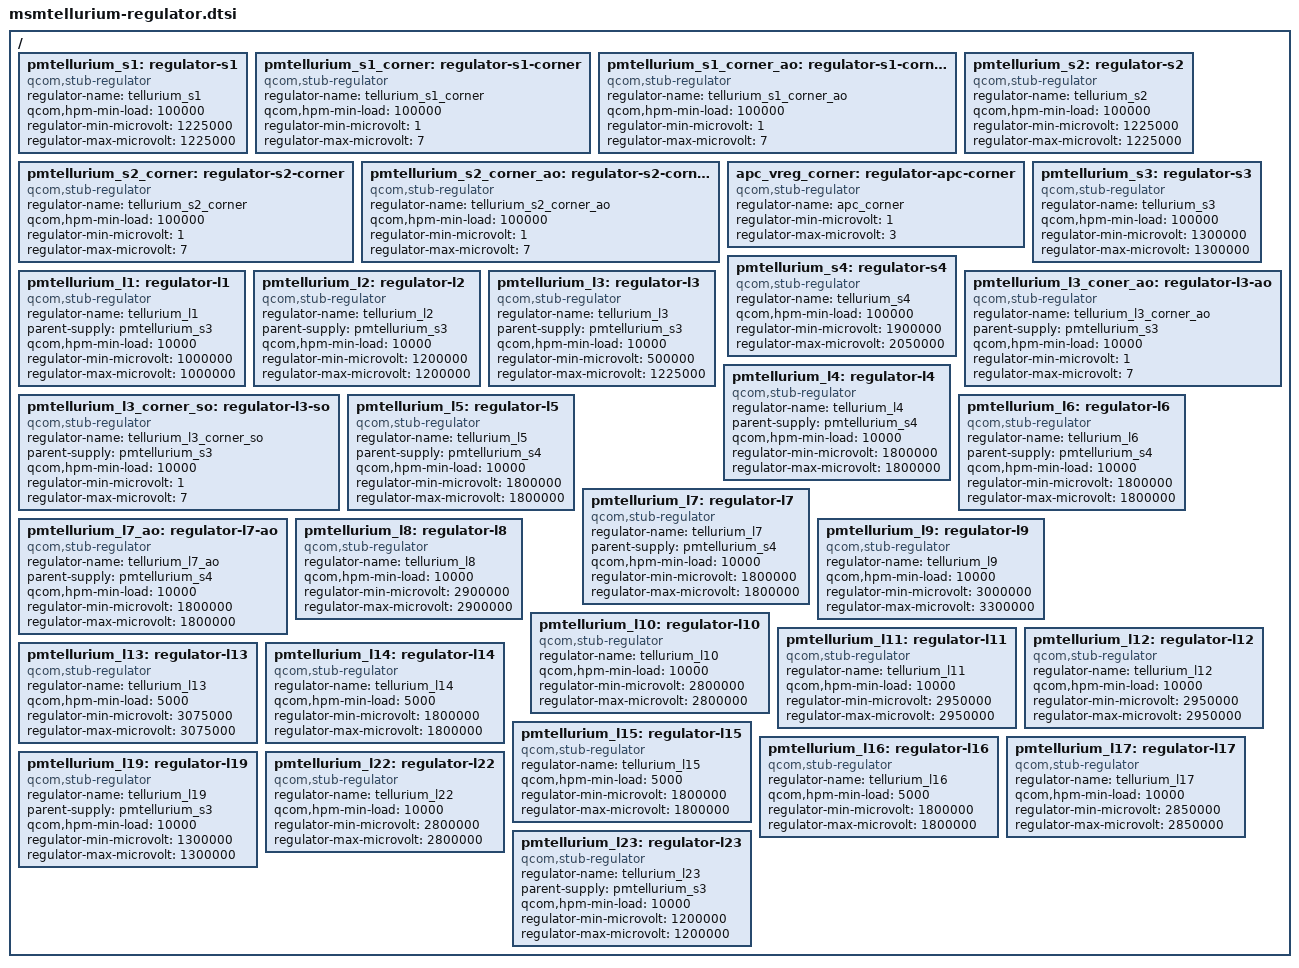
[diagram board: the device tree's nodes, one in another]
/*
 * Copyright (c) 2014, The Linux Foundation. All rights reserved.
 *
 * This program is free software; you can redistribute it and/or modify
 * it under the terms of the GNU General Public License version 2 and
 * only version 2 as published by the Free Software Foundation.
 *
 * This program is distributed in the hope that it will be useful,
 * but WITHOUT ANY WARRANTY; without even the implied warranty of
 * MERCHANTABILITY or FITNESS FOR A PARTICULAR PURPOSE.  See the
 * GNU General Public License for more details.
 */

/* Stub regulators */

/ {
	pmtellurium_s1: regulator-s1 {
		compatible = "qcom,stub-regulator";
		regulator-name = "tellurium_s1";
		qcom,hpm-min-load = <100000>;
		regulator-min-microvolt = <1225000>;
		regulator-max-microvolt = <1225000>;
	};

	pmtellurium_s1_corner: regulator-s1-corner {
		compatible = "qcom,stub-regulator";
		regulator-name = "tellurium_s1_corner";
		qcom,hpm-min-load = <100000>;
		regulator-min-microvolt = <1>;
		regulator-max-microvolt = <7>;
	};

	pmtellurium_s1_corner_ao: regulator-s1-corner-ao {
		compatible = "qcom,stub-regulator";
		regulator-name = "tellurium_s1_corner_ao";
		qcom,hpm-min-load = <100000>;
		regulator-min-microvolt = <1>;
		regulator-max-microvolt = <7>;
	};

	pmtellurium_s2: regulator-s2 {
		compatible = "qcom,stub-regulator";
		regulator-name = "tellurium_s2";
		qcom,hpm-min-load = <100000>;
		regulator-min-microvolt = <1225000>;
		regulator-max-microvolt = <1225000>;
	};

	pmtellurium_s2_corner: regulator-s2-corner {
		compatible = "qcom,stub-regulator";
		regulator-name = "tellurium_s2_corner";
		qcom,hpm-min-load = <100000>;
		regulator-min-microvolt = <1>;
		regulator-max-microvolt = <7>;
	};

	pmtellurium_s2_corner_ao: regulator-s2-corner-ao {
		compatible = "qcom,stub-regulator";
		regulator-name = "tellurium_s2_corner_ao";
		qcom,hpm-min-load = <100000>;
		regulator-min-microvolt = <1>;
		regulator-max-microvolt = <7>;
	};

	apc_vreg_corner: regulator-apc-corner {
		compatible = "qcom,stub-regulator";
		regulator-name = "apc_corner";
		regulator-min-microvolt = <1>;
		regulator-max-microvolt = <3>;
	};

	pmtellurium_s3: regulator-s3 {
		compatible = "qcom,stub-regulator";
		regulator-name = "tellurium_s3";
		qcom,hpm-min-load = <100000>;
		regulator-min-microvolt = <1300000>;
		regulator-max-microvolt = <1300000>;
	};

	pmtellurium_s4: regulator-s4 {
		compatible = "qcom,stub-regulator";
		regulator-name = "tellurium_s4";
		qcom,hpm-min-load = <100000>;
		regulator-min-microvolt = <1900000>;
		regulator-max-microvolt = <2050000>;
	};

	pmtellurium_l1: regulator-l1 {
		compatible = "qcom,stub-regulator";
		regulator-name = "tellurium_l1";
		parent-supply = <&pmtellurium_s3>;
		qcom,hpm-min-load = <10000>;
		regulator-min-microvolt = <1000000>;
		regulator-max-microvolt = <1000000>;
	};

	pmtellurium_l2: regulator-l2 {
		compatible = "qcom,stub-regulator";
		regulator-name = "tellurium_l2";
		parent-supply = <&pmtellurium_s3>;
		qcom,hpm-min-load = <10000>;
		regulator-min-microvolt = <1200000>;
		regulator-max-microvolt = <1200000>;
	};

	pmtellurium_l3: regulator-l3 {
		compatible = "qcom,stub-regulator";
		regulator-name = "tellurium_l3";
		parent-supply = <&pmtellurium_s3>;
		qcom,hpm-min-load = <10000>;
		regulator-min-microvolt = <500000>;
		regulator-max-microvolt = <1225000>;
	};

	pmtellurium_l3_coner_ao: regulator-l3-ao {
		compatible = "qcom,stub-regulator";
		regulator-name = "tellurium_l3_corner_ao";
		parent-supply = <&pmtellurium_s3>;
		qcom,hpm-min-load = <10000>;
		regulator-min-microvolt = <1>;
		regulator-max-microvolt = <7>;
	};

	pmtellurium_l3_corner_so: regulator-l3-so {
		compatible = "qcom,stub-regulator";
		regulator-name = "tellurium_l3_corner_so";
		parent-supply = <&pmtellurium_s3>;
		qcom,hpm-min-load = <10000>;
		regulator-min-microvolt = <1>;
		regulator-max-microvolt = <7>;
	};

	pmtellurium_l4: regulator-l4 {
		compatible = "qcom,stub-regulator";
		regulator-name = "tellurium_l4";
		parent-supply = <&pmtellurium_s4>;
		qcom,hpm-min-load = <10000>;
		regulator-min-microvolt = <1800000>;
		regulator-max-microvolt = <1800000>;
	};

	pmtellurium_l5: regulator-l5 {
		compatible = "qcom,stub-regulator";
		regulator-name = "tellurium_l5";
		parent-supply = <&pmtellurium_s4>;
		qcom,hpm-min-load = <10000>;
		regulator-min-microvolt = <1800000>;
		regulator-max-microvolt = <1800000>;
	};

	pmtellurium_l6: regulator-l6 {
		compatible = "qcom,stub-regulator";
		regulator-name = "tellurium_l6";
		parent-supply = <&pmtellurium_s4>;
		qcom,hpm-min-load = <10000>;
		regulator-min-microvolt = <1800000>;
		regulator-max-microvolt = <1800000>;
	};

	pmtellurium_l7: regulator-l7 {
		compatible = "qcom,stub-regulator";
		regulator-name = "tellurium_l7";
		parent-supply = <&pmtellurium_s4>;
		qcom,hpm-min-load = <10000>;
		regulator-min-microvolt = <1800000>;
		regulator-max-microvolt = <1800000>;
	};

	pmtellurium_l7_ao: regulator-l7-ao {
		compatible = "qcom,stub-regulator";
		regulator-name = "tellurium_l7_ao";
		parent-supply = <&pmtellurium_s4>;
		qcom,hpm-min-load = <10000>;
		regulator-min-microvolt = <1800000>;
		regulator-max-microvolt = <1800000>;
	};

	pmtellurium_l8: regulator-l8 {
		compatible = "qcom,stub-regulator";
		regulator-name = "tellurium_l8";
		qcom,hpm-min-load = <10000>;
		regulator-min-microvolt = <2900000>;
		regulator-max-microvolt = <2900000>;
	};

	pmtellurium_l9: regulator-l9 {
		compatible = "qcom,stub-regulator";
		regulator-name = "tellurium_l9";
		qcom,hpm-min-load = <10000>;
		regulator-min-microvolt = <3000000>;
		regulator-max-microvolt = <3300000>;
	};

	pmtellurium_l10: regulator-l10 {
		compatible = "qcom,stub-regulator";
		regulator-name = "tellurium_l10";
		qcom,hpm-min-load = <10000>;
		regulator-min-microvolt = <2800000>;
		regulator-max-microvolt = <2800000>;
	};

	pmtellurium_l11: regulator-l11 {
		compatible = "qcom,stub-regulator";
		regulator-name = "tellurium_l11";
		qcom,hpm-min-load = <10000>;
		regulator-min-microvolt = <2950000>;
		regulator-max-microvolt = <2950000>;
	};

	pmtellurium_l12: regulator-l12 {
		compatible = "qcom,stub-regulator";
		regulator-name = "tellurium_l12";
		qcom,hpm-min-load = <10000>;
		regulator-min-microvolt = <2950000>;
		regulator-max-microvolt = <2950000>;
	};

	pmtellurium_l13: regulator-l13 {
		compatible = "qcom,stub-regulator";
		regulator-name = "tellurium_l13";
		qcom,hpm-min-load = <5000>;
		regulator-min-microvolt = <3075000>;
		regulator-max-microvolt = <3075000>;
	};

	pmtellurium_l14: regulator-l14 {
		compatible = "qcom,stub-regulator";
		regulator-name = "tellurium_l14";
		qcom,hpm-min-load = <5000>;
		regulator-min-microvolt = <1800000>;
		regulator-max-microvolt = <1800000>;
	};

	pmtellurium_l15: regulator-l15 {
		compatible = "qcom,stub-regulator";
		regulator-name = "tellurium_l15";
		qcom,hpm-min-load = <5000>;
		regulator-min-microvolt = <1800000>;
		regulator-max-microvolt = <1800000>;
	};

	pmtellurium_l16: regulator-l16 {
		compatible = "qcom,stub-regulator";
		regulator-name = "tellurium_l16";
		qcom,hpm-min-load = <5000>;
		regulator-min-microvolt = <1800000>;
		regulator-max-microvolt = <1800000>;
	};

	pmtellurium_l17: regulator-l17 {
		compatible = "qcom,stub-regulator";
		regulator-name = "tellurium_l17";
		qcom,hpm-min-load = <10000>;
		regulator-min-microvolt = <2850000>;
		regulator-max-microvolt = <2850000>;
	};

	pmtellurium_l19: regulator-l19 {
		compatible = "qcom,stub-regulator";
		regulator-name = "tellurium_l19";
		parent-supply = <&pmtellurium_s3>;
		qcom,hpm-min-load = <10000>;
		regulator-min-microvolt = <1300000>;
		regulator-max-microvolt = <1300000>;
	};

	pmtellurium_l22: regulator-l22 {
		compatible = "qcom,stub-regulator";
		regulator-name = "tellurium_l22";
		qcom,hpm-min-load = <10000>;
		regulator-min-microvolt = <2800000>;
		regulator-max-microvolt = <2800000>;
	};

	pmtellurium_l23: regulator-l23 {
		compatible = "qcom,stub-regulator";
		regulator-name = "tellurium_l23";
		parent-supply = <&pmtellurium_s3>;
		qcom,hpm-min-load = <10000>;
		regulator-min-microvolt = <1200000>;
		regulator-max-microvolt = <1200000>;
	};
};
